# UART3 register map
Vendor: Texas Instruments
Peripheral module from a debugger description file (folder DM50x).
Registers are 32-bit, read-write, reset 0x0 unless marked. A register's access mark holds for its fields unless they carry their own. Offsets are as the file gives them; lines under a group give offsets from that group; [hi:lo] are bit positions; {n}, {i} and the like mark numbered series; 'fields as' and 'values as' point back to an identical list; <NAME> marks a mode.

## UART3
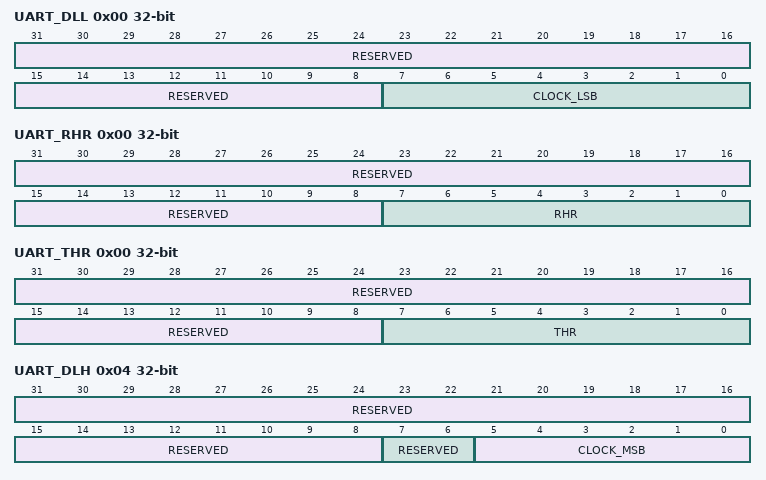
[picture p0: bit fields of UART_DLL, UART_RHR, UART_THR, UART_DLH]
0x00 UART_DLL — This register, with, stores the 14-bit divisor for generation of the baud clock in the baud rate generator. DLH stores the most-significant part of the divisor. DLL stores the least-significant part of the divisor.
  [31:8] RESERVED — Read returns 0. Write has no effect.
  [7:0] CLOCK_LSB — Stores the 8-bit LSB divisor value
0x00 UART_RHR ro (reset mask 0xFFFFFF00) — The receiver section consists of the receiver holding register (RHR) and the receiver shift register. The RHR is a 64-byte FIFO. The receiver shift register receives serial data from RX input. The data is converted to parallel data and moved to the RHR. If the FIFO is disabled, location 0 of the FIFO stores the single data character.Note:If an overflow occurs, the data in the RHR is not overwritten.
  [31:8] RESERVED — Read returns 0
  [7:0] RHR — Receive holding register
0x00 UART_THR wo (reset mask 0xFFFFFF00) — The transmitter section consists of the transmit holding register (THR) and the transmit shift register. The THR is a 64-byte FIFO. The local host (LH) writes data to the THR. The data is placed in the transmit shift register where it is shifted out serially on the TX output. If the FIFO is disabled, location 0 of the FIFO stores the data.
  [31:8] RESERVED — Write has no effect.
  [7:0] THR — Transmit holding register
0x04 UART_DLH — This register, with, stores the 14-bit divisor for generating the baud clock in the baud rate generator. DLH stores the most-significant part of the divisor. DLL stores the least-significant part of the divisor.
  [31:8] RESERVED — Read returns 0. Write has no effect.
  [7:6] RESERVED — Read returns 0. Write has no effect.
  [5:0] CLOCK_MSB — Stores the 6-bit MSB divisor value
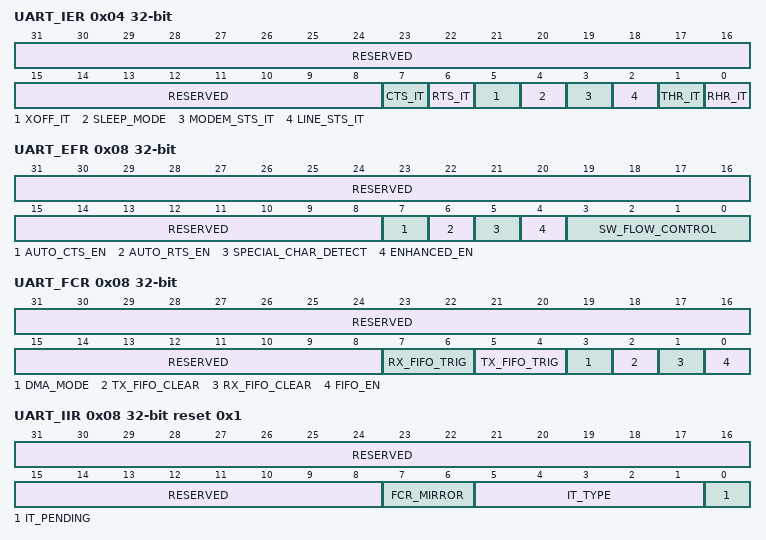
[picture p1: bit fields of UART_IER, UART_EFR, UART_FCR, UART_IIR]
0x04 UART_IER — Interrupt enable register
  [31:8] RESERVED — Read returns 0. Write has no effect.
  [7] CTS_IT
    0=Disables_the_CTS*_interrupt; 1=Enables_the_CTS*_interrupt
  [6] RTS_IT
    0=Disables_the_RTS*_interrupt; 1=Enables_the_RTS*_interrupt
  [5] XOFF_IT
    0=Disables_the_XOFF_interrupt; 1=Enables_the_XOFF_interrupt
  [4] SLEEP_MODE
    0=Disables_sleep_mode; 1=Enables sleep mode (stop baud rate clock when the module is inactive)
  [3] MODEM_STS_IT
    0=Disables the modem status register interrupt; 1=Enables the modem status register interrupt
  [2] LINE_STS_IT
    0=Disables the receiver line status interrupt; 1=Enables the receiver line status interrupt
  [1] THR_IT
    0=Disables_the_THR_interrupt; 1=Enables_the_THR_interrupt
  [0] RHR_IT
    0=RHR_0 (Disables the RHR interrupt and time-out interrupt); 1=RHR_1 (Enables the RHR interrupt and time-out interrupt)
0x08 UART_EFR — Enhanced feature register
  [31:8] RESERVED — Read returns 0. Write has no effect.
  [7] AUTO_CTS_EN — Auto-CTS enable bit
    0=Normal_operation; 1=CTS*_1 (Auto-CTS flow control is enabled. Transmission is halted when the CTS* pin is high (inactive).)
  [6] AUTO_RTS_EN — Auto-RTS enable bit
    0=Normal_operation; 1=RTS*_RX_FIFO_HALT_RX_FIFO_RESTORE_1 (Auto-RTS flow control is enabled. RTS* pin goes high (inactive) when the RX FIFO HALT trigger level,[3:0], is reached, and goes low (active) when the RX FIFO RESTORE transmission trigger level is reached.)
  [5] SPECIAL_CHAR_DETECT
    0=Normal_operation; 1=XOFF2_RX_FIFO_1 (Special character detect enable. Received data is compared with XOFF2 data. If a match occurs, the received data is transferred to the RX FIFO and the[4] bit is set to 1 to indicate that a special character was detected.)
  [4] ENHANCED_EN — Enhanced functions write enable bit
    0=IER_0 (Disables writing to IER bits 4-7, bits 4-5, and bits 5-7.); 1=IER_1 (Enables writing to IER bits 4-7, bits 4-5, and bits 5-7.)
  [3:0] SW_FLOW_CONTROL — Combinations of software flow control can be selected by programming bit 3 - bit 0. See.
0x08 UART_FCR wo — FIFO control register
  [31:8] RESERVED — Write has no effect.
  [7:6] RX_FIFO_TRIG — Sets the trigger level for the RX FIFO: If UART_SCR[7] = 0 and UART_TLR[7:4] = 0000: 00: 8 characters 01: 16 characters 10: 56 characters 11: 60 characters If UART_SCR[7] = 0 and UART_TLR[7:4] != 0000, RX_FIFO_TRIG is not considered. If UART_SCR[7] = 1, RX_FIFO_TRIG is 2 LSBs of the trigger level (1-63 on 6 bits) with the granularity 1.
  [5:4] TX_FIFO_TRIG — Sets the trigger level for the TX FIFO: If UART_SCR[6] = 0 and UART_TLR[3:0] = 0000: 00: 8 spaces 01: 16 spaces 10: 32 spaces 11: 56 spaces If UART_SCR[6] = 0 and UART_TLR[3:0] != 0000, TX_FIFO_TRIG is not considered. If UART_SCR[6] = 1, TX_FIFO_TRIG is 2 LSBs of the trigger level (1-63 on 6 bits) with the granularity 1
  [3] DMA_MODE — This register is considered ifUART_SCR[0] = 0.
    0=DMA_MODE_0_(No_DMA); 1=DMA_MODE_TX_RX_1 (DMA_MODE 1 (UART_nDMA_REQ[0] in TX (UARTi_DREQ_TX), UART_nDMA_REQ[1] in RX (UARTi_DREQ_RX)))
  [2] TX_FIFO_CLEAR
    0=No_change; 1=TX_FIFO_FIFO._1 (Clears the TX FIFO and resets its counter logic to 0. Returns to 0 after clearing FIFO.)
  [1] RX_FIFO_CLEAR
    0=No_change; 1=RX_FIFO_FIFO._1 (Clears the RX FIFO and resets its counter logic to 0. Returns to 0 after clearing FIFO.)
  [0] FIFO_EN
    0=RX_0 (Disables the transmit and RX FIFOs. The transmit and receive holding registers are 1-byte FIFOs.); 1=RX_1 (Enables the transmit and RX FIFOs. The transmit and receive holding registers are 64-byte FIFOs.)
0x08 UART_IIR ro reset 0x1 — Interrupt identification register.
  [31:8] RESERVED — Read returns 0. Write has no effect.
  [7:6] FCR_MIRROR — Mirror the contents ofUART_FCR[0] on both bits.
  [5:1] IT_TYPE — Read 0x0: Modem interrupt. Priority = 4
    1=THR_interrupt._Priority_=_3; 2=RHR_interrupt._Priority_=_2; 3=IT_TYPE_3_r (Receiver line status error. Priority = 3); 6=Rx_time-out._Priority_=_2; 8=XOFF/special_character._Priority_=_5; 16=CTS,_RTS,_DSR_16 (CTS, RTS, DSR change state from active (low) to inactive (high) Priority = 6)
  [0] IT_PENDING — Read 0x0: An interrupt is pending.
    1=No_interrupt_is_pending
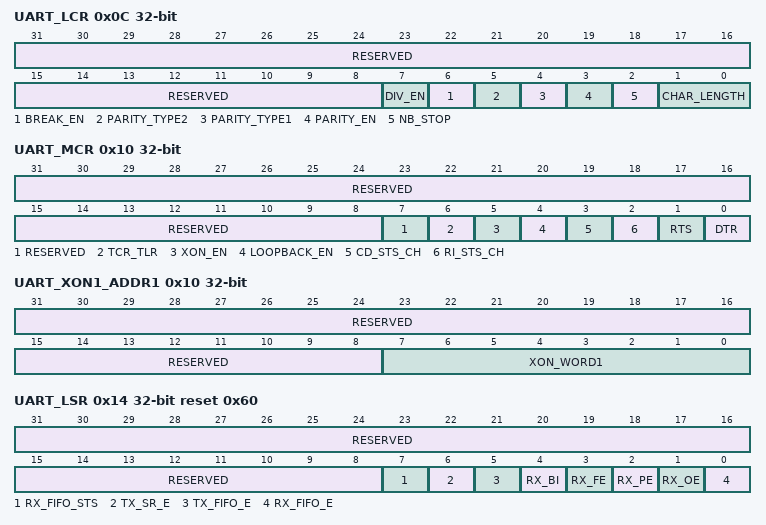
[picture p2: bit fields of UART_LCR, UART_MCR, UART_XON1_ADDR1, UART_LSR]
0x0C UART_LCR — Line control register
  [31:8] RESERVED — Read returns 0. Write has no effect.
  [7] DIV_EN
    0=Normal_operating_condition; 1=Divisor latch enable. Allows access to, , and other registers (see ).
  [6] BREAK_EN — Break control bit
    0=Normal_operating_condition; 1=Forces the transmitter output to go low to alert the communication terminal
  [5] PARITY_TYPE2 — Selects the forced parity format (ifUART_LCR[3] = 1). If UART_LCR[5] = 1 and UART_LCR[4] = 0, the parity bit is forced to 1 in the transmitted and received data. If UART_LCR[5] = 1 and UART_LCR[4] = 1, the parity bit is forced to 0 in the transmitted and received data.
  [4] PARITY_TYPE1
    0=Odd_parity_is_generated_(if[3]_=_1); 1=Even_parity_is_generated_(if[3]_=_1)
  [3] PARITY_EN — 0x0: No parity
    1=A_1 (A parity bit is generated during transmission and the receiver checks for received parity.)
  [2] NB_STOP — Specifies the number of stop-bits
    0=1_stop-bit_(word_length_=_5,_6,_7,_8); 1=1.5 stop-bits (word length = 5) 2 stop-bits (word length = 6, 7, 8)
  [1:0] CHAR_LENGTH — Specifies the word length to be transmitted or received
    {v}={v+5}_bits (v=0..3)
0x10 UART_MCR — Modem control register
  [31:8] RESERVED — Read returns 0. Write has no effect.
  [7] RESERVED — Read returns 0. Write has no effect.
  [6] TCR_TLR — 0x0: No action
    1=Enables_access_to_the_and_registers
  [5] XON_EN — 0x0: Disable XON any function.
    1=Enable_XON_any_function
  [4] LOOPBACK_EN — 0x0: Normal operating mode
    1=MCR[3:0]_1 (Enable local loopback mode (internal). In this mode, the MCR[3:0] signals are looped back into the[7:4] bit field. The transmit output is looped back to the receive input internally.)
  [3] CD_STS_CH — 0x0: In loopback, forces DCD* input high and IRQ outputs to inactive state
    1=DCD*_IRQ_1 (In loopback, forces DCD* input low and IRQ outputs to inactive state)
  [2] RI_STS_CH — 0x0: In loopback, forces RI* input high
    1=In_loopback,_forces_RI*_input_low
  [1] RTS — In loopback, controls theUART_MSR[4] bit. If auto-RTS is enabled, the RTS* output is controlled by hardware flow control.
    0=Force_RTS*_output_to_inactive_(high); 1=Force_RTS*_output_to_active_(low)
  [0] DTR — 0x0: Force DTR* output to inactive (high).
    1=Force_DTR*_output_to_active_(low)
0x10 UART_XON1_ADDR1 — UART mode: XON1 character
  [31:8] RESERVED — Read returns 0. Write has no effect.
  [7:0] XON_WORD1 — Stores the 8-bit XON1 character in UART modes
0x14 UART_LSR ro reset 0x60 — Line status register
  [31:8] RESERVED — Read returns 0.
  [7] RX_FIFO_STS — Read 0x0: Normal operation
    1=RX_FIFO._RX_FIFO._1 (At least one parity error, framing error, or break indication in the RX FIFO. Bit 7 is cleared when no more errors are present in the RX FIFO.)
  [6] TX_SR_E — Read 0x0: Transmitter hold (TX FIFO) and shift registers are not empty.
    1=(TX_FIFO)_1 (Transmitter hold (TX FIFO) and shift registers are empty.)
  [5] TX_FIFO_E — Read 0x0: Transmit hold register (TX FIFO) is not empty.
    1=(TX_FIFO)_1 (Transmit hold register (TX FIFO) is empty. The transmission is not necessarily complete.)
  [4] RX_BI — Read 0x0: No break condition
    1=A_RX_FIFO_RX_1 (A break was detected while the data from the RX FIFO was received (for example, RX input was low for one character + 1 bit time frame).)
  [3] RX_FE — Read 0x0: No framing error in data RX FIFO
    1=RX_FIFO_1 (Framing error occurred in data from RX FIFO (received data did not have a valid stop-bit).)
  [2] RX_PE — Read 0x0: No parity error in data from RX FIFO
    1=Parity_error_in_data_from_RX_FIFO
  [1] RX_OE — Read 0x0: No overrun error
    1=RX_FIFO._RX_FIFO_1 (Overrun error occurred. Set when the character in the receive shift register is not transferred to the RX FIFO. This occurs only when the RX FIFO is full.)
  [0] RX_FIFO_E — Read 0x0: No data in the RX FIFO
    1=RX_FIFO_1 (At least one data character in the RX FIFO)
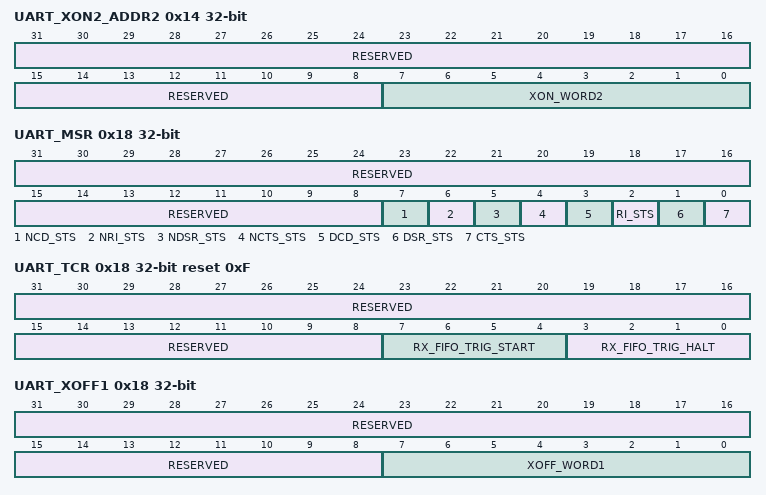
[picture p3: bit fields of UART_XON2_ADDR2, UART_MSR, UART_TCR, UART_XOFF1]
0x14 UART_XON2_ADDR2 — Stores the 8-bit XON2 character in UART moldes
  [31:8] RESERVED — Read returns 0. Write has no effect.
  [7:0] XON_WORD2 — Stores the 8-bit XON2 character in UART modes
0x18 UART_MSR ro (reset mask 0xFFFFFF0F) — Modem status register.
  [31:8] RESERVED — Read returns 0.
  [7] NCD_STS — This bit is the complement of the DCD* input. In loopback mode, it is equivalent toUART_MCR[3].
  [6] NRI_STS — This bit is the complement of the RI* input. In loopback mode, it is equivalent toUART_MCR[2].
  [5] NDSR_STS — This bit is the complement of the DSR* input. In loopback mode, it is equivalent toUART_MCR[0].
  [4] NCTS_STS — This bit is the complement of the CTS* input. In loopback mode, it is equivalent toUART_MCR[1].
  [3] DCD_STS — Indicates that DCD* input (orUART_MCR[3] in loopback) changed. Cleared on a read.
  [2] RI_STS — Indicates that RI* input (orUART_MCR[2] in loopback) changed state from low to high. Cleared on a read.
  [1] DSR_STS
    1=DSR*_1 (Indicates that DSR* input (or[0] in loopback) changed state. Cleared on a read.)
  [0] CTS_STS
    1=CTS*_1 (Indicates that CTS* input (or[1] in loopback) changed state. Cleared on a read.)
0x18 UART_TCR reset 0xF — Transmission control register
  [31:8] RESERVED — Read returns 0. Write has no effect.
  [7:4] RX_FIFO_TRIG_START — RX FIFO trigger level to RESTORE transmission (0 - 60)
  [3:0] RX_FIFO_TRIG_HALT — RX FIFO trigger level to HALT transmission (0 - 60)
0x18 UART_XOFF1 — UART mode XOFF1 character
  [31:8] RESERVED — Read returns 0. Write has no effect.
  [7:0] XOFF_WORD1 — Stores the 8-bit XOFF1 character used in UART modes
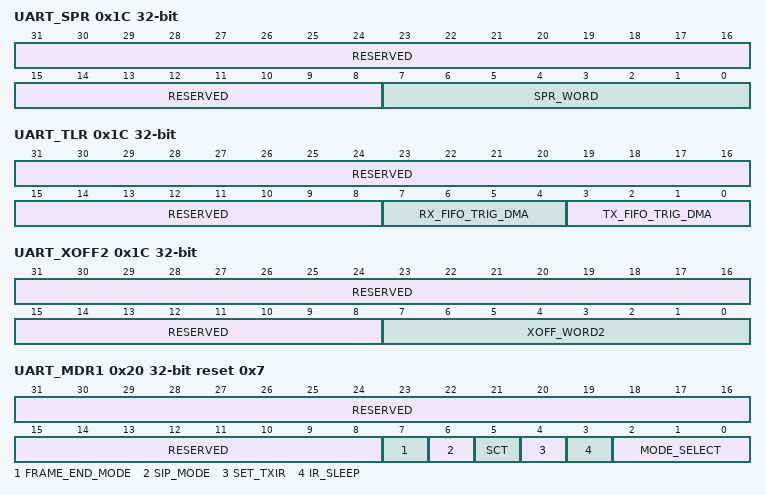
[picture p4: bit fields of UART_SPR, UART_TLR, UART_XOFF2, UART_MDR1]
0x1C UART_SPR — Scratchpad register
  [31:8] RESERVED — Read returns 0. Write has no effect.
  [7:0] SPR_WORD — Scratchpad register
0x1C UART_TLR — Trigger level register
  [31:8] RESERVED — Read returns 0. Write has no effect.
  [7:4] RX_FIFO_TRIG_DMA — Receive FIFO trigger level
  [3:0] TX_FIFO_TRIG_DMA — Transmit FIFO trigger level
0x1C UART_XOFF2 — UART mode XOFF2 character
  [31:8] RESERVED — Read returns 0. Write has no effect.
  [7:0] XOFF_WORD2 — Stores the 8-bit XOFF2 character used in UART modes.
0x20 UART_MDR1 reset 0x7 — Mode definition register 1
  [31:8] RESERVED — Read returns 0. Write has no effect.
  [7] FRAME_END_MODE — Reserved
  [6] SIP_MODE — Reserved
  [5] SCT — Reserved
  [4] SET_TXIR — Reserved
  [3] IR_SLEEP — Reserved
  [2:0] MODE_SELECT — 0x0: UART 16x mode
    2=UART_16x_auto-baud; 3=UART_13x_mode; 7=Disable_(default_state)
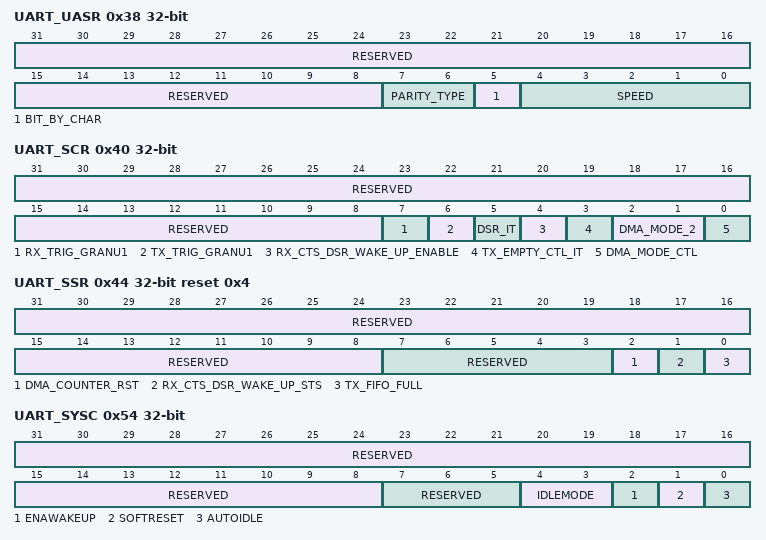
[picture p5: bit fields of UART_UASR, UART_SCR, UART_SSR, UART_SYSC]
0x38 UART_UASR ro — UART autobauding status register
  [31:8] RESERVED — Read returns 0.
  [7:6] PARITY_TYPE — Read 0x0: No parity identified
    1=Parity_space; 2=Even_parity; 3=Odd_parity
  [5] BIT_BY_CHAR — Read 0x0: 7-bit character identified
    1=8-bit_character_identified
  [4:0] SPEED — Used to report the speed identified
    0=No_speed_identified; 1=115,200_baud; 2=57,600_baud; 3=38,400_baud; 4=28,800_baud; 5=19,200_baud; 6=14,400_baud; 7=9,600_baud; 8=4,800_baud; 9=2,400_baud; 10=1,200_baud
0x40 UART_SCR — Supplementary control register
  [31:8] RESERVED — Read returns 0. Write has no effect.
  [7] RX_TRIG_GRANU1 — 0x0: Disables the granularity of 1 for trigger RX level
    1=RX_1 (Enables the granularity of 1 for trigger RX level)
  [6] TX_TRIG_GRANU1 — 0x0: Disables the granularity of 1 for trigger TX level
    1=TX_1 (Enables the granularity of 1 for trigger TX level)
  [5] DSR_IT — NOT USED IN THIS DEVICE
  [4] RX_CTS_DSR_WAKE_UP_ENABLE — 0x0: Disables the wake-up interrupt and clears SSR[1]
    1=RX_CTS*_1 (Waits for a falling edge of pins RX or CTS* to generate an interrupt)
  [3] TX_EMPTY_CTL_IT — 0x0: Normal mode for THR interrupt (see UART mode interrupts table)
    1=THR_TX_FIFO_TX_1 (The THR interrupt is generated when TX FIFO and TX shift register are empty.)
  [2:1] DMA_MODE_2 — Used to specify the DMA mode valid if theUART_SCR[0] bit = 1
    0=DMA_mode_0_(no_DMA); 1=DMA_TX,_RX)_1 (DMA mode 1 (UART_nDMA_REQ[0] in TX, UART_nDMA_REQ[1] in RX)); 2=DMA_mode_2_(UART_nDMA_REQ[0]_in_RX); 3=DMA_mode_3_(UART_nDMA_REQ[0]_in_TX)
  [0] DMA_MODE_CTL — 0x0: The DMA_MODE is set withUART_FCR[3].
    1=The_DMA_MODE_is_set_with[2:1]
0x44 UART_SSR access per field reset 0x4 — Supplementary status register
  [31:8] RESERVED ro — Read returns 0.
  [7:3] RESERVED ro — Read returns 0.
  [2] DMA_COUNTER_RST rw — 0x0: The DMA counter will not be reset if the corresponding FIFO is reset (throughUART_FCR[1] or UART_FCR[2]).
    1=DMA_FIFO_1 (The DMA counter will be reset if corresponding FIFO is reset (through[1] or [2]).)
  [1] RX_CTS_DSR_WAKE_UP_STS ro — Read 0x0: No falling edge event on RX and CTS*.
    1=A_falling_edge_occurred_on_RX_or_CTS*
  [0] TX_FIFO_FULL ro — Read 0x0: TX FIFO is not full.
    1=TX_FIFO_is_full
0x50 UART_MVR ro reset not defined — Module version register
  [31:0] REV — Revision number
0x54 UART_SYSC access per field — System configuration register
  [31:8] RESERVED rw — Read returns 0. Write has no effect.
  [7:5] RESERVED ro — Read returns 0.
  [4:3] IDLEMODE rw — Power management req/ack control
    0=Force-idle: Idle request is acknowledged unconditionally; 1=No-idle: Idle request is never acknowledged; 2=Smart-idle: Idle request is acknowledged based in module internal activity; 3=Smart-idle Wake-up: Acknowledgement to an idle request is given based in the internal activity of the module. The module is allowed to generate wake-up request.
  [2] ENAWAKEUP rw — Wake-up feature control
    0=Wakeup_is_disabled; 1=Wake-up_capability_is_enabled
  [1] SOFTRESET rw — Software reset. Set this bit to 1 to trigger a module reset. This bit is automatically reset by the hardware. Read returns 0.
    0=Normal_mode; 1=The_module_is_reset
  [0] AUTOIDLE rw — Internal OCP clock gating strategy
    0=Clock_is_running; 1=OCP_OCP_1 (Automatic OCP clock gating strategy is applied, based on OCP interface activity)
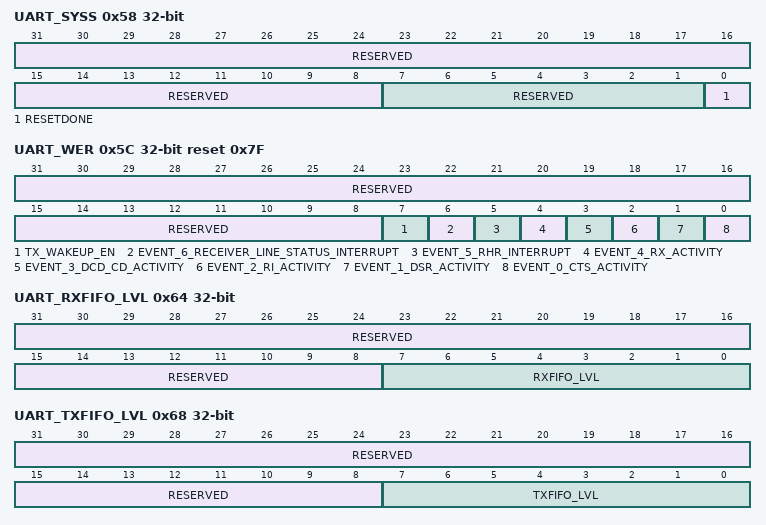
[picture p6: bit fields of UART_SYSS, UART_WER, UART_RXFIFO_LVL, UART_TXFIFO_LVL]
0x58 UART_SYSS ro — System status register
  [31:8] RESERVED — Read returns 0.
  [7:1] RESERVED — Read returns 0.
  [0] RESETDONE — Internal reset monitoring
    0=Internal_module_reset_is_ongoing; 1=Reset_complete
0x5C UART_WER reset 0x7F — Wake-up enable register
  [31:8] RESERVED — Read returns 0. Write has no effect.
  [7] TX_WAKEUP_EN — 0x0: Event is not allowed to wake up the system.
    1=THR_IT_TX_DMA_TX_SATUS_IT._1 (Event can wake up the system: it can be THR_IT or TX_DMA request and/or TX_SATUS_IT.)
  [6] EVENT_6_RECEIVER_LINE_STATUS_INTERRUPT — 0x0: Event is not allowed to wake up the system.
    1=Event_can_wake_up_the_system
  [5] EVENT_5_RHR_INTERRUPT — 0x0: Event is not allowed to wake up the system.
    1=Event_can_wake_up_the_system
  [4] EVENT_4_RX_ACTIVITY — 0x0: Event is not allowed to wake up the system.
    1=Event_can_wake_up_the_system
  [3] EVENT_3_DCD_CD_ACTIVITY — 0x0: Event is not allowed to wake up the system
    1=Event_can_wake_up_the_system
  [2] EVENT_2_RI_ACTIVITY — 0x0: Event is not allowed to wake up the system.
    1=Event_can_wake_up_the_system
  [1] EVENT_1_DSR_ACTIVITY — 0x0: Event is not allowed to wake up the system.
    1=Event_can_wake_up_the_system
  [0] EVENT_0_CTS_ACTIVITY — 0x0: Event is not allowed to wake up the system.
    1=Event_can_wake_up_the_system
0x64 UART_RXFIFO_LVL ro — Level of the RX FIFO
  [31:8] RESERVED — Read returns 0.
  [7:0] RXFIFO_LVL — Shows the number of received bytes in the RX FIFO
0x68 UART_TXFIFO_LVL ro — Level of the TX FIFO
  [31:8] RESERVED — Read returns 0.
  [7:0] TXFIFO_LVL — Shows the number of written bytes in the TX FIFO
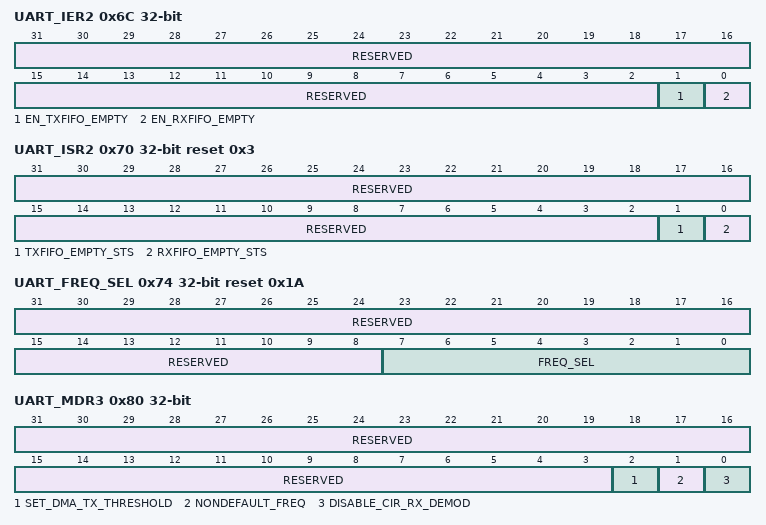
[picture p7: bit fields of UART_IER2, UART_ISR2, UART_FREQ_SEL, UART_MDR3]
0x6C UART_IER2 — Enables RX/TX FIFOs empty corresponding interrupts
  [31:2] RESERVED — Read returns 0. Write has no effect.
  [1] EN_TXFIFO_EMPTY — Enables TX FIFO empty corresponding interrupt
    0=Enables_EN_TXFIFO_EMPTY_interrupt; 1=Disables_EN_TXFIFO_EMPTY_interrupt
  [0] EN_RXFIFO_EMPTY — Enables RX FIFO empty corresponding interrupt
    0=Enables_EN_RXFIFO_EMPTY_interrupt; 1=Disables_EN_RXFIFO_EMPTY_interrupt
0x70 UART_ISR2 reset 0x3 — Status of RX/TX FIFOs empty corresponding interrupts
  [31:2] RESERVED — Read returns 0. Write has no effect.
  [1] TXFIFO_EMPTY_STS — Used to generate interrupt if the TX_FIFO is empty (software flow control)
    0=TXFIFO_EMPTY_interrupt_not_pending; 1=TXFIFO_EMPTY_interrupt_pending
  [0] RXFIFO_EMPTY_STS — Used to generate interrupt if the RX_FIFO is empty (software flow control)
    0=RXFIFO_EMPTY_interrupt_not_pending; 1=RXFIFO_EMPTY_interrupt_pending
0x74 UART_FREQ_SEL reset 0x1A — Sample per bit selector
  [31:8] RESERVED — Read returns 0. Write has no effect.
  [7:0] FREQ_SEL — Sets the sample per bit if nondefault frequency is used.UART_MDR3[1] must be set to 1 after this value is set. Must be equal to or higher then 6.
0x80 UART_MDR3 — Mode definition register 3
  [31:3] RESERVED — Read returns 0. Write has no effect.
  [2] SET_DMA_TX_THRESHOLD — Enable to set different TXDMA threshold inUART_TX_DMA_THRESHOLD register.
  [1] NONDEFAULT_FREQ — Used to enable the NONDEFAULT fclk frequencies.
    0=NONDEFAULT_0 (Disables using NONDEFAULT fclk frequencies.); 1=NONDEFAULT_1 (Enables using NONDEFAULT fclk frequencies (set and / ).)
  [0] DISABLE_CIR_RX_DEMOD — Used to enable CIR RX demodulation. CIR IS NOT SUPPORTED
    0=Enables_CIR_RX_demodulation; 1=Disables_CIR_RX_demodulation
0x84 UART_TX_DMA_THRESHOLD — Use to manually set the TX DMA threshold level. [2] SET_TX_DMA_THRESHOLD must be 1 and must be value + tx_trigger_level = 64 (TX FIFO size). If not, 64-tx_trigger_level will be used without modifying the value of this register.
  [5:0] TX_DMA_THRESHOLD — Used to manually set the TX DMA threshold level
